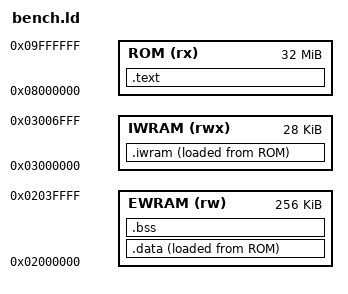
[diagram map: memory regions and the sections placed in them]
ENTRY(_start)
MEMORY {
    ROM (rx) : ORIGIN = 0x08000000, LENGTH = 32M
    EWRAM (rw) : ORIGIN = 0x02000000, LENGTH = 256K
    IWRAM (rwx) : ORIGIN = 0x03000000, LENGTH = 28K
}
SECTIONS {
    .text : {
        KEEP(*(.text.start))
        *(.text*)
        *(.rodata*)
        . = ALIGN(4);
    } > ROM
    .iwram : {
        __iwram_start = .;
        *(.iwram*)
        . = ALIGN(4);
        __iwram_end = .;
    } > IWRAM AT> ROM
    __iwram_load = LOADADDR(.iwram);
    .data : {
        __data_start = .;
        *(.data*)
        . = ALIGN(4);
        __data_end = .;
    } > EWRAM AT> ROM
    __data_load = LOADADDR(.data);
    .bss (NOLOAD) : {
        __bss_start = .;
        *(.bss*) *(COMMON)
        . = ALIGN(4);
        __bss_end = .;
    } > EWRAM
    /DISCARD/ : { *(.comment) *(.ARM.exidx*) *(.ARM.extab*) }
}
